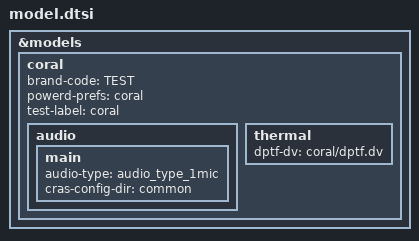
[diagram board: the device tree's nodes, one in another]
/*
 * Copyright 2017 The Chromium OS Authors. All rights reserved.
 *
 * Use of this source code is governed by a BSD-style license that can be
 * found in the LICENSE file.
 */

&models {
	coral: coral {
		brand-code = "TEST";
		powerd-prefs = "coral";
		test-label = "coral";
		audio {
			main {
				audio-type = <&audio_type_1mic>;
				cras-config-dir = "common";
			};
		};
		thermal {
			dptf-dv = "coral/dptf.dv";
		};
	};
};
